# FM33FG0XXA register map
File version: 1.0
CPU: SC000 r1p0, little endian, MPU, no FPU, 3 interrupt priority bits
Registers are 32-bit, read-only, reset 0x0 unless marked. A register's access mark holds for its fields unless they carry their own. Offsets are from the block's base; [hi:lo] are bit positions; {n}, {i} and the like mark numbered series; 'fields as' and 'values as' point back to an identical list.

## FLS — FLS module information
Base 0x40001000
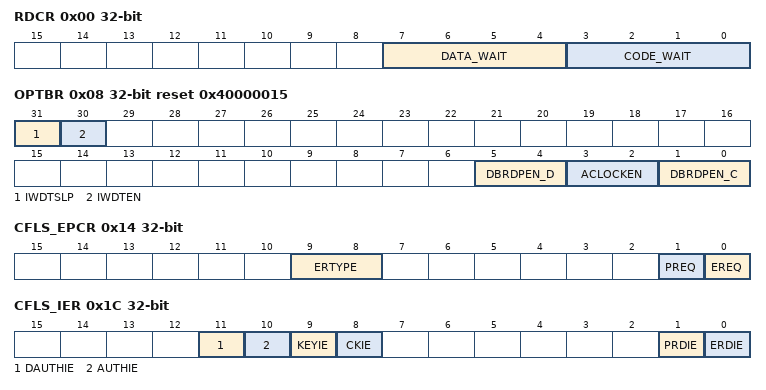
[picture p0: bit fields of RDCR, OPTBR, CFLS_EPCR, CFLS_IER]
0x00 RDCR rw — Flash Read Control Register
  [7:4] DATA_WAIT — DATA_WAIT field description
  [3:0] CODE_WAIT — CODE_WAIT field description
0x08 OPTBR access per field reset 0x40000015 — Flash Option Bytes Register
  [31] IWDTSLP ro — IWDTSLP field description
  [30] IWDTEN ro — IWDTEN field description
  [5:4] DBRDPEN_D rw — DBRDPEN_D field description
  [3:2] ACLOCKEN rw — ACLOCKEN field description
  [1:0] DBRDPEN_C rw — DBRDPEN_C field description
0x14 CFLS_EPCR rw — Code Flash Erase/Program Control Register
  [9:8] ERTYPE — ERTYPE field description
  [1] PREQ — PREQ field description
  [0] EREQ — EREQ field description
0x18 CFLS_KEY wo — Code Flash Key Register
  [31:0] KEY — KEY field description
0x1C CFLS_IER rw — CodeFlash Interrupt Enable Register
  [11] DAUTHIE — DAUTHIE field description
  [10] AUTHIE — AUTHIE field description
  [9] KEYIE — KEYIE field description
  [8] CKIE — CKIE field description
  [1] PRDIE — PRDIE field description
  [0] ERDIE — ERDIE field description
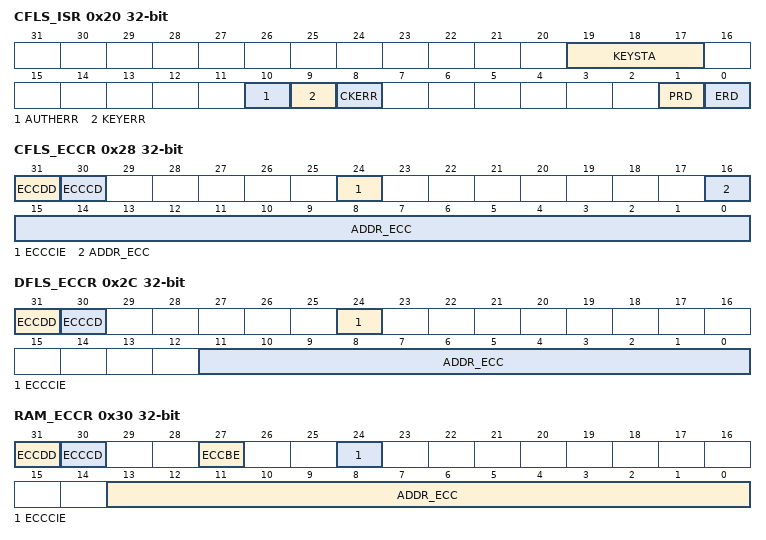
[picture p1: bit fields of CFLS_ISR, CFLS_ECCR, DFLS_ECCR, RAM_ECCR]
0x20 CFLS_ISR access per field — Code Flash Interrupt Status Register
  [19:17] KEYSTA ro — KEYSTA field description
  [10] AUTHERR rw — AUTHERR field description
  [9] KEYERR rw — KEYERR field description
  [8] CKERR rw — CKERR field description
  [1] PRD rw — PRD field description
  [0] ERD rw — ERD field description
0x28 CFLS_ECCR access per field
  [31] ECCDD rw — ECCDD field description
  [30] ECCCD rw — ECCCD field description
  [24] ECCCIE rw — ECCCIE field description
  [16:0] ADDR_ECC ro — ADDR_ECC field description
0x2C DFLS_ECCR access per field
  [31] ECCDD rw — ECCDD field description
  [30] ECCCD rw — ECCCD field description
  [24] ECCCIE rw — ECCCIE field description
  [11:0] ADDR_ECC ro — ADDR_ECC field description
0x30 RAM_ECCR access per field
  [31] ECCDD rw — ECCDD field description
  [30] ECCCD rw — ECCCD field description
  [27] ECCBE rw — ECCBE field description
  [24] ECCCIE rw — ECCCIE field description
  [13:0] ADDR_ECC ro — ADDR_ECC field description
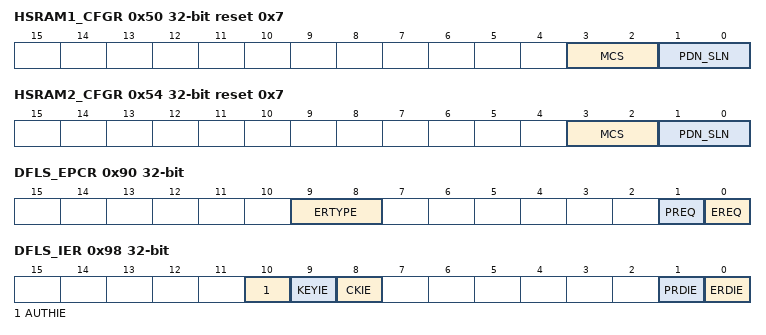
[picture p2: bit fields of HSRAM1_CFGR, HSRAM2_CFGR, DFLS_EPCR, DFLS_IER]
0x50 HSRAM1_CFGR rw reset 0x7
  [3:2] MCS — MCS field description
  [1:0] PDN_SLN — PDN_SLN field description
0x54 HSRAM2_CFGR rw reset 0x7
  fields as HSRAM1_CFGR
{0x5C+4i} ACLOCK{i} rw (i=1..4) — Flash Application Code Lock Register{i}
  [31:0] LOCK{i} — LOCK{i} field description
0x90 DFLS_EPCR rw — Data Flash Erase/Program Control Register
  fields as CFLS_EPCR
0x94 DFLS_KEY wo — Data Flash Key Register
  [31:0] KEY — KEY field description
0x98 DFLS_IER rw — Data Flash Interrupt Enable Register
  [10] AUTHIE — AUTHIE field description
  [9] KEYIE — KEYIE field description
  [8] CKIE — CKIE field description
  [1] PRDIE — PRDIE field description
  [0] ERDIE — ERDIE field description
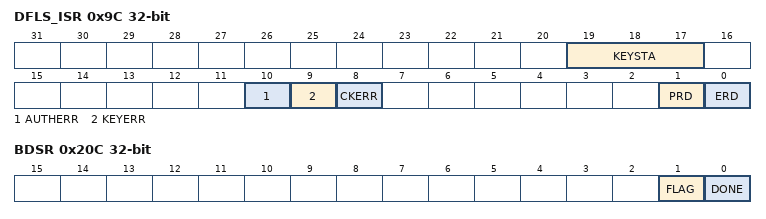
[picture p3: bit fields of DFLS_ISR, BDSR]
0x9C DFLS_ISR access per field — Data Flash Interrupt Status Register
  fields as CFLS_ISR
0x100 RAM_RAW0
  [31:0] RAWDATA — RAWDATA field description
0x104 RAM_RAW1
  [6:0] RAWECC — RAWECC field description
0x108 DFLS_RAW0
  [31:0] RAWDATA — RAWDATA field description
0x10C DFLS_RAW1
  [6:0] RAWECC — RAWECC field description
0x200 BDVR wo
  [31:0] BDVR — BDVR field description
0x204 BDCR0 rw
  [31:0] BDCR0 — BDCR0 field description
0x208 BDCR1 rw
  [31:0] BDCR1 — BDCR1 field description
0x20C BDSR
  [1] FLAG — FLAG field description
  [0] DONE — DONE field description

## PMU — PMU module information
Base 0x40002000
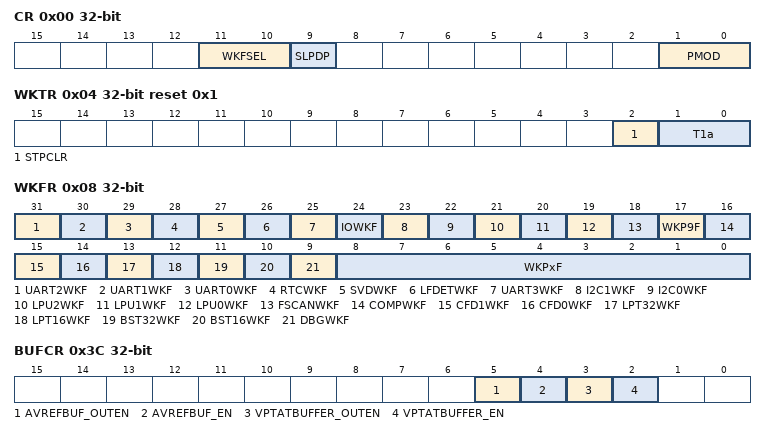
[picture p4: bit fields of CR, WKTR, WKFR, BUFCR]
0x00 CR rw — Power Management Control Register
  [11:10] WKFSEL — WKFSEL field description
  [9] SLPDP — SLPDP field description
  [1:0] PMOD — PMOD field description
0x04 WKTR rw reset 0x1 — Wakeup Time Register
  [2] STPCLR — STPCLR field description
  [1:0] T1a — T1a field description
0x08 WKFR access per field — Wakeup Source Flags Register
  [31] UART2WKF ro — UART2WKF field description
  [30] UART1WKF ro — UART1WKF field description
  [29] UART0WKF ro — UART0WKF field description
  [28] RTCWKF ro — RTCWKF field description
  [27] SVDWKF ro — SVDWKF field description
  [26] LFDETWKF ro — LFDETWKF field description
  [25] UART3WKF ro — UART3WKF field description
  [24] IOWKF ro — IOWKF field description
  [23] I2C1WKF ro — I2C1WKF field description
  [22] I2C0WKF ro — I2C0WKF field description
  [21] LPU2WKF ro — LPU2WKF field description
  [20] LPU1WKF ro — LPU1WKF field description
  [19] LPU0WKF ro — LPU0WKF field description
  [18] FSCANWKF ro — FSCANWKF field description
  [17] WKP9F rw — WKP9F field description
  [16] COMPWKF ro — COMPWKF field description
  [15] CFD1WKF ro — CFD1WKF field description
  [14] CFD0WKF ro — CFD0WKF field description
  [13] LPT32WKF ro — LPT32WKF field description
  [12] LPT16WKF ro — LPT16WKF field description
  [11] BST32WKF ro — BST32WKF field description
  [10] BST16WKF ro — BST16WKF field description
  [9] DBGWKF rw — DBGWKF field description
  [8:0] WKPxF rw — WKPxF field description
0x0C IER rw — PMU Interrupt Enable Register
  [1] SLPEIE — SLPEIE field description
0x10 ISR rw — PMU Interrupt and Status Register
  [1] SLPEIF — SLPEIF field description
0x3C BUFCR rw — PMU Analog Buffer Control Register
  [5] AVREFBUF_OUTEN — AVREFBUF_OUTEN field description
  [4] AVREFBUF_EN — AVREFBUF_EN field description
  [3] VPTATBUFFER_OUTEN — VPTATBUFFER_OUTEN field description
  [2] VPTATBUFFER_EN — VPTATBUFFER_EN field description
0x50 PTAT_CR rw — PMU PTAT Control Register
  [0] PTAT_EN — PTAT_EN field description
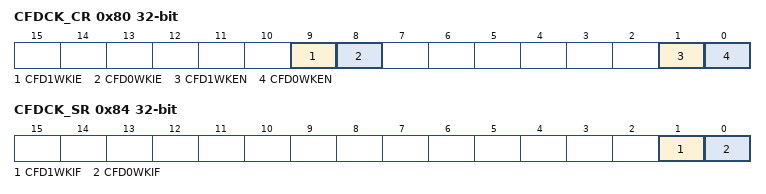
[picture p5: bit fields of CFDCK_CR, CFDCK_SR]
0x80 CFDCK_CR rw
  [9] CFD1WKIE — CFD1WKIE field description
  [8] CFD0WKIE — CFD0WKIE field description
  [1] CFD1WKEN — CFD1WKEN field description
  [0] CFD0WKEN — CFD0WKEN field description
0x84 CFDCK_SR rw
  [1] CFD1WKIF — CFD1WKIF field description
  [0] CFD0WKIF — CFD0WKIF field description
